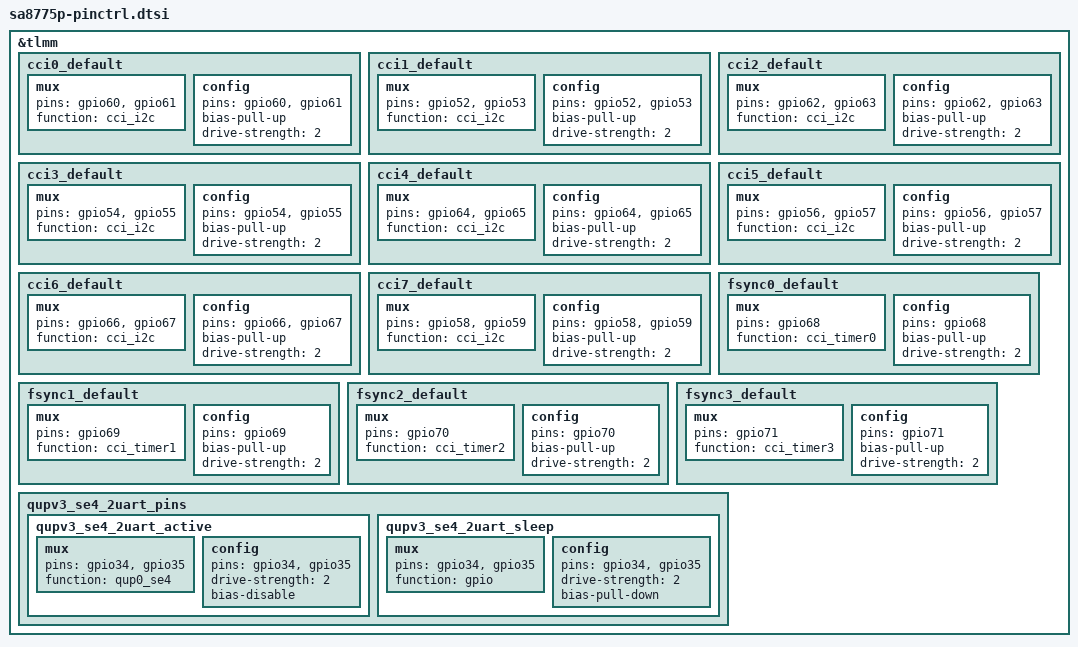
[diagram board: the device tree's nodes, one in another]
// SPDX-License-Identifier: GPL-2.0-only
/*
* Copyright (c) 2023 Qualcomm Innovation Center, Inc. All rights reserved.
*/

&tlmm {

	cci0_default: cci0_default {
		mux {
			/* CLK, DATA */
			pins = "gpio60","gpio61";
			function = "cci_i2c";
		};
		config {
			pins = "gpio60","gpio61";
			bias-pull-up; /* PULL UP*/
			drive-strength = <2>; /* 2 MA */
		};
	};

	cci1_default: cci1_default {
		mux {
			/* CLK, DATA */
			pins = "gpio52","gpio53";
			function = "cci_i2c";
		};

		config {
			pins = "gpio52","gpio53";
			bias-pull-up; /* PULL UP*/
			drive-strength = <2>; /* 2 MA */
		};
	};

	cci2_default: cci2_default {
		mux {
			/* CLK, DATA */
			pins = "gpio62","gpio63";
			function = "cci_i2c";
		};
		config {
			pins = "gpio62","gpio63";
			bias-pull-up; /* PULL UP*/
			drive-strength = <2>; /* 2 MA */
		};
	};

	cci3_default: cci3_default {
		mux {
			/* CLK, DATA */
			pins = "gpio54","gpio55";
			function = "cci_i2c";
		};

		config {
			pins = "gpio54","gpio55";
			bias-pull-up; /* PULL UP*/
			drive-strength = <2>; /* 2 MA */
		};
	};

	cci4_default: cci4_default {
		mux {
			/* CLK, DATA */
			pins = "gpio64","gpio65";
			function = "cci_i2c";
		};

		config {
			pins = "gpio64","gpio65";
			bias-pull-up; /* PULL UP*/
			drive-strength = <2>; /* 2 MA */
		};
	};

	cci5_default: cci5_default {
		mux {
			/* CLK, DATA */
			pins = "gpio56","gpio57";
			function = "cci_i2c";
		};

		config {
			pins = "gpio56","gpio57";
			bias-pull-up; /* PULL UP*/
			drive-strength = <2>; /* 2 MA */
		};
	};

	cci6_default: cci6_default {
		mux {
			/* CLK, DATA */
			pins = "gpio66","gpio67";
			function = "cci_i2c";
		};

		config {
			pins = "gpio66","gpio67";
			bias-pull-up; /* PULL UP*/
			drive-strength = <2>; /* 2 MA */
		};
	};

	cci7_default: cci7_default {
		mux {
			/* CLK, DATA */
			pins = "gpio58","gpio59";
			function = "cci_i2c";
		};

	config {
			pins = "gpio58","gpio59";
			bias-pull-up; /* PULL UP*/
			drive-strength = <2>; /* 2 MA */
		};
	};

	fsync0_default: fsync0_default {
		mux {
			/* CLK, DATA */
			pins = "gpio68";
			function = "cci_timer0";
		};

		config {
			pins = "gpio68";
			bias-pull-up; /* PULL UP*/
			drive-strength = <2>; /* 2 MA */
		};
	};

	fsync1_default: fsync1_default {
		mux {
			/* CLK, DATA */
			pins = "gpio69";
			function = "cci_timer1";
		};

		config {
			pins = "gpio69";
			bias-pull-up; /* PULL UP*/
			drive-strength = <2>; /* 2 MA */
		};
	};

	fsync2_default: fsync2_default {
		mux {
			/* CLK, DATA */
			pins = "gpio70";
			function = "cci_timer2";
		};

		config {
			pins = "gpio70";
			bias-pull-up; /* PULL UP*/
			drive-strength = <2>; /* 2 MA */
		};
	};

	fsync3_default: fsync3_default {
		mux {
			/* CLK, DATA */
			pins = "gpio71";
			function = "cci_timer3";
		};

		config {
			pins = "gpio71";
			bias-pull-up; /* PULL UP*/
			drive-strength = <2>; /* 2 MA */
		};
	};

	qupv3_se4_2uart_pins: qupv3_se4_2uart_pins {
		qupv3_se4_2uart_active: qupv3_se4_2uart_active {
			mux {
				pins = "gpio34", "gpio35";
				function = "qup0_se4";
			};

			config {
				pins = "gpio34", "gpio35";
				drive-strength = <2>;
				bias-disable;
			};
		};

		qupv3_se4_2uart_sleep: qupv3_se4_2uart_sleep {
			mux {
				pins = "gpio34", "gpio35";
				function = "gpio";
			};

			config {
				pins = "gpio34", "gpio35";
				drive-strength = <2>;
				bias-pull-down;
			};
		};
	};

};
